# STM32G471 register map
File version: 2.1
CPU: CM4 r0p1, little endian, MPU, FPU, 4 interrupt priority bits
Registers are 32-bit, read-write, reset 0x0 unless marked. A register's access mark holds for its fields unless they carry their own. Offsets are from the block's base; [hi:lo] are bit positions.

## FLASH
Base 0x40022000
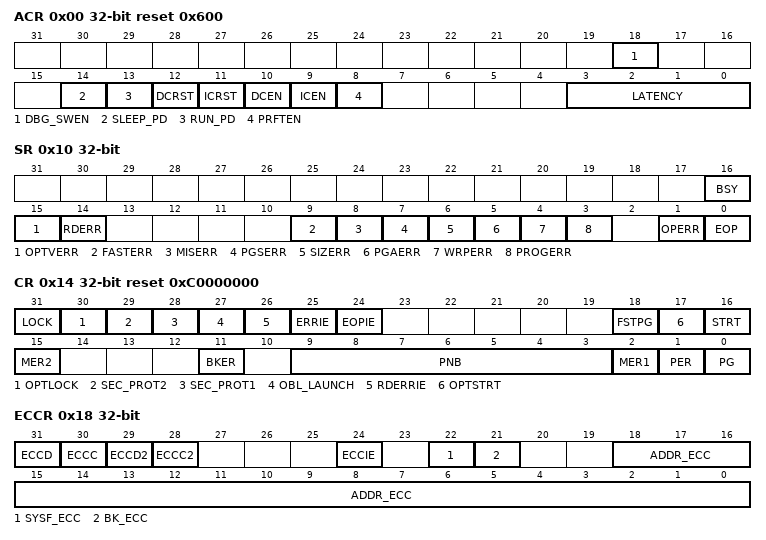
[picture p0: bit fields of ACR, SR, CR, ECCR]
0x00 ACR reset 0x600 — Access control register
  [18] DBG_SWEN — Debug software enable
  [14] SLEEP_PD — Flash Power-down mode during Low-power sleep mode
  [13] RUN_PD — Flash Power-down mode during Low-power run mode
  [12] DCRST — Data cache reset
  [11] ICRST — Instruction cache reset
  [10] DCEN — Data cache enable
  [9] ICEN — Instruction cache enable
  [8] PRFTEN — Prefetch enable
  [3:0] LATENCY
    0=Wait0 (Zero Wait States (Vcore Boost 1 (<= 34MHz), Vcore Normal 1 (<= 30MHz), Vcore 2 (<= 12MHz)); 1=Wait1 (One Wait State (Vcore Boost 1 (<= 68MHz), Vcore Normal 1 (<= 60MHz), Vcore 2 (<= 24MHz)); 2=Wait2 (Two Wait States (Vcore Boost 1 (<= 102MHz), Vcore Normal 1 (<= 90MHz), Vcore 2 (<= 26MHz)); 3=Wait3 (Three Wait States (Vcore Boost 1 (<= 136MHz), Vcore Normal 1 (<= 120MHz)); 4=Wait4 (Four Wait States (Vcore Boost 1 (<= 170MHz), Vcore Normal 1 (<= 150MHz))
0x04 PDKEYR wo — Power down key register
  [31:0] PDKEYR — RUN_PD in FLASH_ACR key
0x08 KEYR wo — Flash key register
0x0C OPTKEYR wo — Option byte key register
  [31:0] OPTKEYR — Option byte key
0x10 SR access per field — Status register
  [16] BSY ro — Busy
  [15] OPTVERR rw — Option validity error
  [14] RDERR rw — PCROP read error
  [9] FASTERR rw — Fast programming error
  [8] MISERR rw — Fast programming data miss error
  [7] PGSERR rw — Programming sequence error
  [6] SIZERR rw — Size error
  [5] PGAERR rw — Programming alignment error
  [4] WRPERR rw — Write protected error
  [3] PROGERR rw — Programming error
  [1] OPERR rw — Operation error
  [0] EOP rw — End of operation
0x14 CR reset 0xC0000000 — Flash control register
  [31] LOCK — FLASH_CR Lock
  [30] OPTLOCK — Options Lock
  [29] SEC_PROT2 — Securable memory area protection bit for bank 2.
  [28] SEC_PROT1
  [27] OBL_LAUNCH — Force the option byte loading
  [26] RDERRIE — PCROP read error interrupt enable
  [25] ERRIE — Error interrupt enable
  [24] EOPIE — End of operation interrupt enable
  [18] FSTPG — Fast programming
  [17] OPTSTRT — Options modification start
  [16] STRT — Start
  [15] MER2 — Bank 2 Mass erase
  [11] BKER — Bank erase
    0=Bank 1 is selected for page erase; 1=Bank 2 is selected for page erase
  [9:3] PNB — Page number
  [2] MER1 — Bank 1 Mass erase
  [1] PER — Page erase
  [0] PG — Programming
0x18 ECCR access per field — Flash ECC register
  [31] ECCD rw — ECC detection
  [30] ECCC rw — ECC correction
  [29] ECCD2 rw — ECC2 detection
  [28] ECCC2 rw — ECC correction
  [24] ECCIE rw
  [22] SYSF_ECC ro
  [21] BK_ECC ro
  [18:0] ADDR_ECC ro — ECC fail address
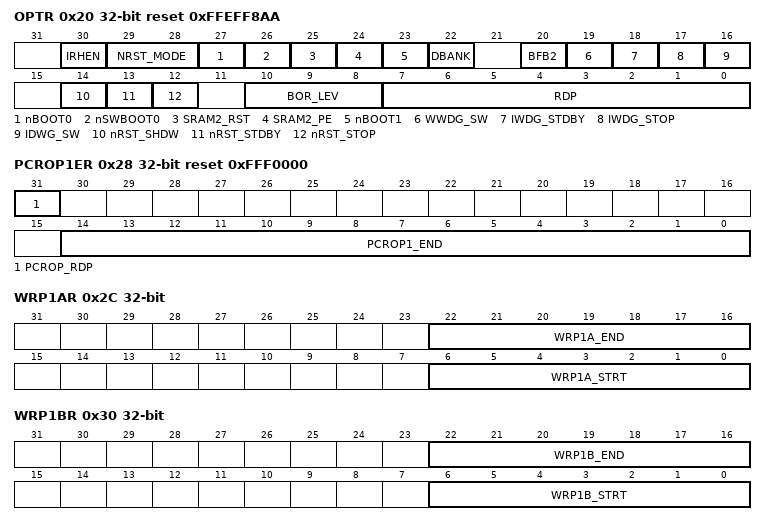
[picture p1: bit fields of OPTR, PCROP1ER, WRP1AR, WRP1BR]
0x20 OPTR reset 0xFFEFF8AA — Flash option register
  [30] IRHEN
  [29:28] NRST_MODE
  [27] nBOOT0
  [26] nSWBOOT0
  [25] SRAM2_RST — SRAM2 Erase when system reset
  [24] SRAM2_PE — SRAM2 parity check enable
  [23] nBOOT1 — Boot configuration
  [22] DBANK — Single or dual bank mode
    0=Single-bank mode with 128 bits data read width; 1=Dual-bank mode with 64 bits data
  [20] BFB2 — Bank to boot from
    0=Disabled (Boot from memory bank 1); 1=Enabled (Boot from memory bank 2)
  [19] WWDG_SW — Window watchdog selection
  [18] IWDG_STDBY — Independent watchdog counter freeze in Standby mode
  [17] IWDG_STOP — Independent watchdog counter freeze in Stop mode
  [16] IDWG_SW — Independent watchdog selection
  [14] nRST_SHDW
  [13] nRST_STDBY
  [12] nRST_STOP
  [10:8] BOR_LEV — BOR reset Level
  [7:0] RDP — Read protection level
0x24 PCROP1SR reset 0xFFFF0000 — Flash Bank 1 PCROP Start address register
  [14:0] PCROP1_STRT — Bank 1 PCROP area start offset
0x28 PCROP1ER reset 0xFFF0000 — Flash Bank 1 PCROP End address register
  [31] PCROP_RDP — PCROP area preserved when RDP level decreased
  [14:0] PCROP1_END — Bank 1 PCROP area end offset
0x2C WRP1AR — Flash Bank 1 WRP area A address register
  [22:16] WRP1A_END — Bank 1 WRP first area A end offset
  [6:0] WRP1A_STRT — Bank 1 WRP first area start offset
0x30 WRP1BR — Flash Bank 1 WRP area B address register
  [22:16] WRP1B_END — Bank 1 WRP second area B start offset
  [6:0] WRP1B_STRT — Bank 1 WRP second area B end offset
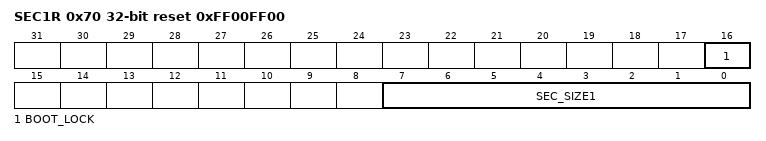
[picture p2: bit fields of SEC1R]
0x70 SEC1R reset 0xFF00FF00 — securable area bank1 register
  [16] BOOT_LOCK, [7:0] SEC_SIZE1
